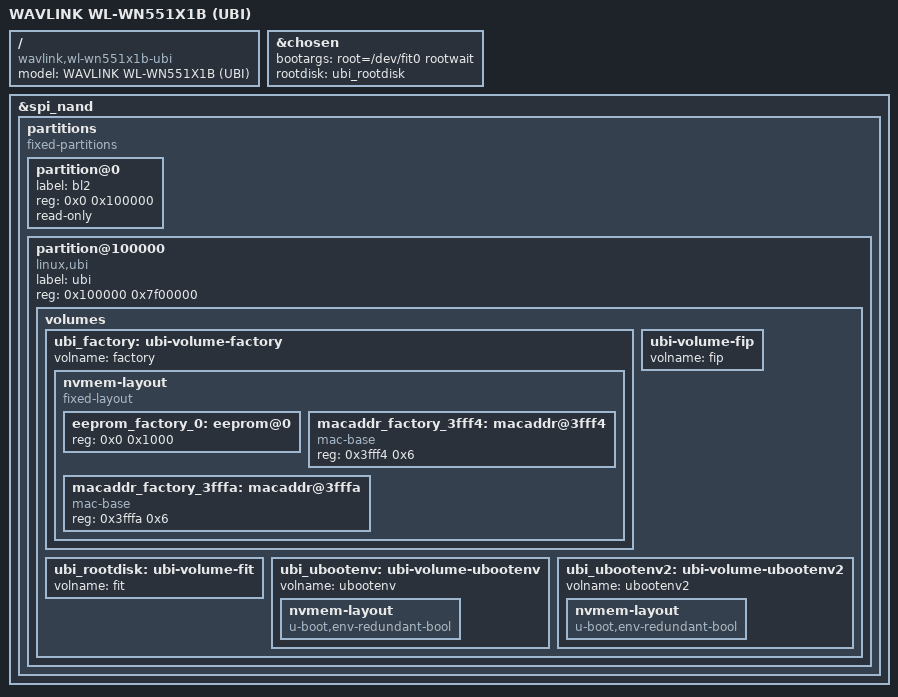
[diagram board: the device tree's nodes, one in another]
// SPDX-License-Identifier: GPL-2.0-only OR MIT

/dts-v1/;

#include "mt7981b-wavlink-wl-wn551x1b-common.dtsi"

/ {
	model = "WAVLINK WL-WN551X1B (UBI)";
	compatible = "wavlink,wl-wn551x1b-ubi", "mediatek,mt7981b";
};

&chosen {
	bootargs = "root=/dev/fit0 rootwait";
	rootdisk = <&ubi_rootdisk>;
};

/delete-node/ &partitions;

&spi_nand {
	partitions {
		compatible = "fixed-partitions";
		#address-cells = <1>;
		#size-cells = <1>;

		partition@0 {
			label = "bl2";
			reg = <0x0 0x100000>;
			read-only;
		};

		partition@100000 {
			label = "ubi";
			reg = <0x100000 0x7f00000>;
			compatible = "linux,ubi";

			volumes {
				ubi_factory: ubi-volume-factory {
					volname = "factory";
				};

                ubi-volume-fip {
                    volname = "fip";
                };

				ubi_rootdisk: ubi-volume-fit {
					volname = "fit";
				};

				ubi_ubootenv: ubi-volume-ubootenv {
					volname = "ubootenv";
				};
				
                ubi_ubootenv2: ubi-volume-ubootenv2 {
					volname = "ubootenv2";
				};

		    };
	    };
    };
};

&ubi_factory {
	nvmem-layout {
		compatible = "fixed-layout";
		#address-cells = <1>;
		#size-cells = <1>;

		eeprom_factory_0: eeprom@0 {
			reg = <0x0 0x1000>;
		};

		macaddr_factory_3fff4: macaddr@3fff4 {
            compatible = "mac-base";
			reg = <0x3fff4 0x6>;
            #nvmem-cell-cells = <1>;
        };

		macaddr_factory_3fffa: macaddr@3fffa {
            compatible = "mac-base";
			reg = <0x3fffa 0x6>;
            #nvmem-cell-cells = <1>;
       	};
	};
};

&ubi_ubootenv {
	nvmem-layout {
		compatible = "u-boot,env-redundant-bool";
	};
};

&ubi_ubootenv2 {
	nvmem-layout {
		compatible = "u-boot,env-redundant-bool";
	};
};
